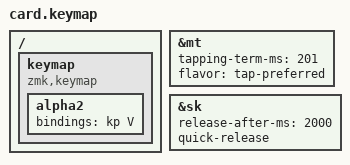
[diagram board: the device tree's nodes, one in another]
/*
 * Copyright (c) 2020 The ZMK Contributors
 *
 * SPDX-License-Identifier: MIT
 */

#include <behaviors.dtsi>
#include <dt-bindings/zmk/keys.h>
#include <dt-bindings/zmk/bt.h>
#include <dt-bindings/zmk/mouse.h>



&mt {
    tapping-term-ms = <201>;
    flavor = "tap-preferred";
 };
&sk {
     release-after-ms = <2000>;
     quick-release;
 };

/ { 

    
       keymap {
                compatible = "zmk,keymap";
                
       		alpha2 {
		bindings = <
		&kp V
		>;
		};
	};
};
